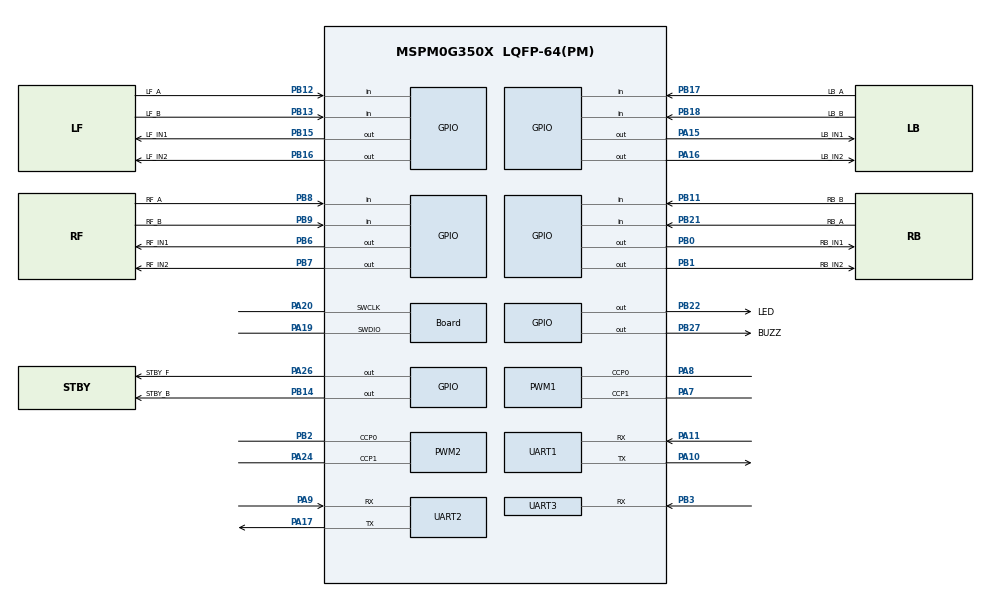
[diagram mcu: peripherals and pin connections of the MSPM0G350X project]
/**
 * These arguments were used when this file was generated. They will be automatically applied on subsequent loads
 * via the GUI or CLI. Run CLI with '--help' for additional information on how to override these arguments.
 * @cliArgs --device "MSPM0G350X" --package "LQFP-64(PM)" --part "Default" --product "mspm0_sdk@1.30.00.03"
 * @versions {"tool":"1.19.0+3426"}
 */

/**
 * Import the modules used in this configuration.
 */
const ADC12         = scripting.addModule("/ti/driverlib/ADC12", {}, false);
const ADC121        = ADC12.addInstance();
const GPIO          = scripting.addModule("/ti/driverlib/GPIO", {}, false);
const GPIO1         = GPIO.addInstance();
const GPIO2         = GPIO.addInstance();
const GPIO3         = GPIO.addInstance();
const GPIO4         = GPIO.addInstance();
const GPIO5         = GPIO.addInstance();
const GPIO6         = GPIO.addInstance();
const PWM           = scripting.addModule("/ti/driverlib/PWM", {}, false);
const PWM1          = PWM.addInstance();
const PWM2          = PWM.addInstance();
const SYSCTL        = scripting.addModule("/ti/driverlib/SYSCTL");
const SYSTICK       = scripting.addModule("/ti/driverlib/SYSTICK");
const TIMER         = scripting.addModule("/ti/driverlib/TIMER", {}, false);
const TIMER1        = TIMER.addInstance();
const TIMER2        = TIMER.addInstance();
const TIMER3        = TIMER.addInstance();
const UART          = scripting.addModule("/ti/driverlib/UART", {}, false);
const UART1         = UART.addInstance();
const UART2         = UART.addInstance();
const UART3         = UART.addInstance();
const ProjectConfig = scripting.addModule("/ti/project_config/ProjectConfig");

/**
 * Write custom configuration values to the imported modules.
 */
const divider6       = system.clockTree["PLL_CLK2X_DIV"];
divider6.divideValue = 4;

const divider7       = system.clockTree["PLL_PDIV"];
divider7.divideValue = 2;

const divider9       = system.clockTree["UDIV"];
divider9.divideValue = 2;

const multiplier2         = system.clockTree["PLL_QDIV"];
multiplier2.multiplyValue = 10;

const mux8       = system.clockTree["HSCLKMUX"];
mux8.inputSelect = "HSCLKMUX_SYSPLL2X";

ADC121.$name                             = "adckey";
ADC121.sampClkDiv                        = "DL_ADC12_CLOCK_DIVIDE_8";
ADC121.enabledInterrupts                 = ["DL_ADC12_INTERRUPT_MEM0_RESULT_LOADED"];
ADC121.adcMem0_name                      = "key";
ADC121.sampleTime0                       = "5 ms";
ADC121.peripheral.$assign                = "ADC0";
ADC121.peripheral.adcPin0.$assign        = "PA27";
ADC121.adcPin0Config.hideOutputInversion = scripting.forceWrite(false);
ADC121.adcPin0Config.$name               = "ti_driverlib_gpio_GPIOPinGeneric8";

const Board                       = scripting.addModule("/ti/driverlib/Board", {}, false);
Board.peripheral.$assign          = "DEBUGSS";
Board.peripheral.swclkPin.$assign = "PA20";
Board.peripheral.swdioPin.$assign = "PA19";

GPIO1.port                               = "PORTB";
GPIO1.$name                              = "REMINDER";
GPIO1.associatedPins.create(2);
GPIO1.associatedPins[0].$name            = "LED";
GPIO1.associatedPins[0].ioStructure      = "SD";
GPIO1.associatedPins[0].assignedPin      = "22";
GPIO1.associatedPins[0].pin.$assign      = "PB22";
GPIO1.associatedPins[1].internalResistor = "PULL_UP";
GPIO1.associatedPins[1].$name            = "BUZZ";
GPIO1.associatedPins[1].pin.$assign      = "PB27";

GPIO2.$name                              = "ENCODER_LF";
GPIO2.port                               = "PORTB";
GPIO2.associatedPins.create(2);
GPIO2.associatedPins[0].direction        = "INPUT";
GPIO2.associatedPins[0].ioStructure      = "SD";
GPIO2.associatedPins[0].interruptEn      = true;
GPIO2.associatedPins[0].internalResistor = "PULL_UP";
GPIO2.associatedPins[0].$name            = "LF_A";
GPIO2.associatedPins[0].assignedPin      = "12";
GPIO2.associatedPins[0].polarity         = "RISE_FALL";
GPIO2.associatedPins[0].pin.$assign      = "PB12";
GPIO2.associatedPins[1].direction        = "INPUT";
GPIO2.associatedPins[1].ioStructure      = "SD";
GPIO2.associatedPins[1].internalResistor = "PULL_UP";
GPIO2.associatedPins[1].$name            = "LF_B";
GPIO2.associatedPins[1].assignedPin      = "13";
GPIO2.associatedPins[1].interruptEn      = true;
GPIO2.associatedPins[1].polarity         = "RISE_FALL";
GPIO2.associatedPins[1].pin.$assign      = "PB13";

GPIO3.$name                              = "ENCODER_LB";
GPIO3.port                               = "PORTB";
GPIO3.associatedPins.create(2);
GPIO3.associatedPins[0].direction        = "INPUT";
GPIO3.associatedPins[0].ioStructure      = "SD";
GPIO3.associatedPins[0].interruptEn      = true;
GPIO3.associatedPins[0].internalResistor = "PULL_UP";
GPIO3.associatedPins[0].$name            = "LB_A";
GPIO3.associatedPins[0].assignedPin      = "17";
GPIO3.associatedPins[0].polarity         = "RISE_FALL";
GPIO3.associatedPins[0].pin.$assign      = "PB17";
GPIO3.associatedPins[1].direction        = "INPUT";
GPIO3.associatedPins[1].ioStructure      = "SD";
GPIO3.associatedPins[1].interruptEn      = true;
GPIO3.associatedPins[1].internalResistor = "PULL_UP";
GPIO3.associatedPins[1].$name            = "LB_B";
GPIO3.associatedPins[1].assignedPin      = "18";
GPIO3.associatedPins[1].polarity         = "RISE_FALL";
GPIO3.associatedPins[1].pin.$assign      = "PB18";

GPIO4.$name                              = "ENCODER_RF";
GPIO4.port                               = "PORTB";
GPIO4.associatedPins.create(2);
GPIO4.associatedPins[0].direction        = "INPUT";
GPIO4.associatedPins[0].ioStructure      = "SD";
GPIO4.associatedPins[0].interruptEn      = true;
GPIO4.associatedPins[0].internalResistor = "PULL_UP";
GPIO4.associatedPins[0].assignedPin      = "8";
GPIO4.associatedPins[0].$name            = "RF_A";
GPIO4.associatedPins[0].polarity         = "RISE_FALL";
GPIO4.associatedPins[0].pin.$assign      = "PB8";
GPIO4.associatedPins[1].direction        = "INPUT";
GPIO4.associatedPins[1].ioStructure      = "SD";
GPIO4.associatedPins[1].interruptEn      = true;
GPIO4.associatedPins[1].internalResistor = "PULL_UP";
GPIO4.associatedPins[1].assignedPin      = "9";
GPIO4.associatedPins[1].$name            = "RF_B";
GPIO4.associatedPins[1].polarity         = "RISE_FALL";
GPIO4.associatedPins[1].pin.$assign      = "PB9";

GPIO5.$name                              = "ENCODER_RB";
GPIO5.port                               = "PORTB";
GPIO5.associatedPins.create(2);
GPIO5.associatedPins[0].direction        = "INPUT";
GPIO5.associatedPins[0].ioStructure      = "SD";
GPIO5.associatedPins[0].interruptEn      = true;
GPIO5.associatedPins[0].internalResistor = "PULL_UP";
GPIO5.associatedPins[0].$name            = "RB_A";
GPIO5.associatedPins[0].assignedPin      = "21";
GPIO5.associatedPins[0].polarity         = "RISE_FALL";
GPIO5.associatedPins[0].pin.$assign      = "PB21";
GPIO5.associatedPins[1].direction        = "INPUT";
GPIO5.associatedPins[1].ioStructure      = "SD";
GPIO5.associatedPins[1].interruptEn      = true;
GPIO5.associatedPins[1].internalResistor = "PULL_UP";
GPIO5.associatedPins[1].assignedPin      = "11";
GPIO5.associatedPins[1].$name            = "RB_B";
GPIO5.associatedPins[1].polarity         = "RISE_FALL";
GPIO5.associatedPins[1].pin.$assign      = "PB11";

GPIO6.$name                              = "MOTOR_DRV";
GPIO6.associatedPins.create(10);
GPIO6.associatedPins[0].$name            = "STBY_F";
GPIO6.associatedPins[0].ioStructure      = "SD";
GPIO6.associatedPins[0].internalResistor = "PULL_UP";
GPIO6.associatedPins[0].pin.$assign      = "PA26";
GPIO6.associatedPins[1].$name            = "STBY_B";
GPIO6.associatedPins[1].ioStructure      = "SD";
GPIO6.associatedPins[1].internalResistor = "PULL_UP";
GPIO6.associatedPins[1].pin.$assign      = "PB14";
GPIO6.associatedPins[2].$name            = "LF_IN1";
GPIO6.associatedPins[2].ioStructure      = "SD";
GPIO6.associatedPins[2].internalResistor = "PULL_UP";
GPIO6.associatedPins[2].pin.$assign      = "PB15";
GPIO6.associatedPins[3].$name            = "LF_IN2";
GPIO6.associatedPins[3].ioStructure      = "SD";
GPIO6.associatedPins[3].internalResistor = "PULL_UP";
GPIO6.associatedPins[3].pin.$assign      = "PB16";
GPIO6.associatedPins[4].$name            = "LB_IN1";
GPIO6.associatedPins[4].ioStructure      = "SD";
GPIO6.associatedPins[4].internalResistor = "PULL_UP";
GPIO6.associatedPins[4].assignedPort     = "PORTA";
GPIO6.associatedPins[4].assignedPin      = "15";
GPIO6.associatedPins[4].pin.$assign      = "PA15";
GPIO6.associatedPins[5].$name            = "LB_IN2";
GPIO6.associatedPins[5].ioStructure      = "SD";
GPIO6.associatedPins[5].internalResistor = "PULL_UP";
GPIO6.associatedPins[5].assignedPort     = "PORTA";
GPIO6.associatedPins[5].assignedPin      = "16";
GPIO6.associatedPins[5].pin.$assign      = "PA16";
GPIO6.associatedPins[6].$name            = "RF_IN1";
GPIO6.associatedPins[6].ioStructure      = "SD";
GPIO6.associatedPins[6].internalResistor = "PULL_UP";
GPIO6.associatedPins[6].pin.$assign      = "PB6";
GPIO6.associatedPins[7].$name            = "RF_IN2";
GPIO6.associatedPins[7].ioStructure      = "SD";
GPIO6.associatedPins[7].internalResistor = "PULL_UP";
GPIO6.associatedPins[7].pin.$assign      = "PB7";
GPIO6.associatedPins[8].$name            = "RB_IN1";
GPIO6.associatedPins[8].ioStructure      = "SD";
GPIO6.associatedPins[8].internalResistor = "PULL_UP";
GPIO6.associatedPins[8].pin.$assign      = "PB0";
GPIO6.associatedPins[9].$name            = "RB_IN2";
GPIO6.associatedPins[9].ioStructure      = "SD";
GPIO6.associatedPins[9].internalResistor = "PULL_UP";
GPIO6.associatedPins[9].pin.$assign      = "PB1";

PWM1.timerStartTimer                    = true;
PWM1.pwmMode                            = "EDGE_ALIGN_UP";
PWM1.clockPrescale                      = 2;
PWM1.timerCount                         = 1600;
PWM1.$name                              = "PWM_MOTOR_L";
PWM1.peripheral.$assign                 = "TIMA0";
PWM1.peripheral.ccp0Pin.$assign         = "PA8";
PWM1.peripheral.ccp1Pin.$assign         = "PA7";
PWM1.PWM_CHANNEL_0.$name                = "ti_driverlib_pwm_PWMTimerCC0";
PWM1.PWM_CHANNEL_1.$name                = "ti_driverlib_pwm_PWMTimerCC1";
PWM1.ccp0PinConfig.direction            = scripting.forceWrite("OUTPUT");
PWM1.ccp0PinConfig.hideOutputInversion  = scripting.forceWrite(false);
PWM1.ccp0PinConfig.onlyInternalResistor = scripting.forceWrite(false);
PWM1.ccp0PinConfig.passedPeripheralType = scripting.forceWrite("Digital");
PWM1.ccp0PinConfig.$name                = "ti_driverlib_gpio_GPIOPinGeneric4";
PWM1.ccp1PinConfig.direction            = scripting.forceWrite("OUTPUT");
PWM1.ccp1PinConfig.hideOutputInversion  = scripting.forceWrite(false);
PWM1.ccp1PinConfig.onlyInternalResistor = scripting.forceWrite(false);
PWM1.ccp1PinConfig.passedPeripheralType = scripting.forceWrite("Digital");
PWM1.ccp1PinConfig.$name                = "ti_driverlib_gpio_GPIOPinGeneric5";

PWM2.$name                              = "PWM_MOTOR_R";
PWM2.clockPrescale                      = 2;
PWM2.timerCount                         = 1600;
PWM2.timerStartTimer                    = true;
PWM2.pwmMode                            = "EDGE_ALIGN_UP";
PWM2.peripheral.$assign                 = "TIMA1";
PWM2.peripheral.ccp0Pin.$assign         = "PB2";
PWM2.peripheral.ccp1Pin.$assign         = "PA24";
PWM2.PWM_CHANNEL_0.$name                = "ti_driverlib_pwm_PWMTimerCC2";
PWM2.PWM_CHANNEL_1.$name                = "ti_driverlib_pwm_PWMTimerCC3";
PWM2.ccp0PinConfig.direction            = scripting.forceWrite("OUTPUT");
PWM2.ccp0PinConfig.hideOutputInversion  = scripting.forceWrite(false);
PWM2.ccp0PinConfig.onlyInternalResistor = scripting.forceWrite(false);
PWM2.ccp0PinConfig.passedPeripheralType = scripting.forceWrite("Digital");
PWM2.ccp0PinConfig.$name                = "ti_driverlib_gpio_GPIOPinGeneric6";
PWM2.ccp1PinConfig.direction            = scripting.forceWrite("OUTPUT");
PWM2.ccp1PinConfig.hideOutputInversion  = scripting.forceWrite(false);
PWM2.ccp1PinConfig.onlyInternalResistor = scripting.forceWrite(false);
PWM2.ccp1PinConfig.passedPeripheralType = scripting.forceWrite("Digital");
PWM2.ccp1PinConfig.$name                = "ti_driverlib_gpio_GPIOPinGeneric7";

SYSCTL.clockTreeEn = true;

SYSTICK.periodEnable      = true;
SYSTICK.period            = 32000;
SYSTICK.interruptEnable   = true;
SYSTICK.interruptPriority = "0";
SYSTICK.systickEnable     = true;

TIMER1.timerStartTimer    = true;
TIMER1.timerMode          = "PERIODIC";
TIMER1.timerClkDiv        = 8;
TIMER1.interrupts         = ["ZERO"];
TIMER1.timerClkPrescale   = 40;
TIMER1.timerPeriod        = "10 ms";
TIMER1.$name              = "ENCODER";
TIMER1.peripheral.$assign = "TIMG7";

TIMER2.timerClkDiv        = 8;
TIMER2.timerClkPrescale   = 40;
TIMER2.timerMode          = "PERIODIC";
TIMER2.timerStartTimer    = true;
TIMER2.interrupts         = ["ZERO"];
TIMER2.$name              = "PID";
TIMER2.timerPeriod        = "10 ms";
TIMER2.peripheral.$assign = "TIMG6";

TIMER3.$name              = "ADC_BUTTON";
TIMER3.timerClkPrescale   = 32;
TIMER3.timerPeriod        = "50 ms";
TIMER3.timerStartTimer    = true;
TIMER3.interrupts         = ["ZERO"];
TIMER3.timerMode          = "PERIODIC";
TIMER3.peripheral.$assign = "TIMG0";

UART1.$name                    = "UART_0";
UART1.enableDMARX              = false;
UART1.enableDMATX              = false;
UART1.enabledInterrupts        = ["RX"];
UART1.rxFifoThreshold          = "DL_UART_RX_FIFO_LEVEL_ONE_ENTRY";
UART1.txFifoThreshold          = "DL_UART_TX_FIFO_LEVEL_3_4_EMPTY";
UART1.peripheral.$assign       = "UART0";
UART1.peripheral.rxPin.$assign = "PA11";
UART1.peripheral.txPin.$assign = "PA10";
UART1.txPinConfig.$name        = "ti_driverlib_gpio_GPIOPinGeneric0";
UART1.rxPinConfig.$name        = "ti_driverlib_gpio_GPIOPinGeneric1";

UART2.$name                    = "UART_1";
UART2.enabledInterrupts        = ["RX"];
UART2.rxFifoThreshold          = "DL_UART_RX_FIFO_LEVEL_ONE_ENTRY";
UART2.txFifoThreshold          = "DL_UART_TX_FIFO_LEVEL_3_4_EMPTY";
UART2.peripheral.$assign       = "UART1";
UART2.peripheral.rxPin.$assign = "PA9";
UART2.peripheral.txPin.$assign = "PA17";
UART2.txPinConfig.$name        = "ti_driverlib_gpio_GPIOPinGeneric2";
UART2.rxPinConfig.$name        = "ti_driverlib_gpio_GPIOPinGeneric3";

UART3.$name                    = "UART_2";
UART3.enableDMARX              = false;
UART3.enableDMATX              = false;
UART3.enabledInterrupts        = ["RX"];
UART3.rxFifoThreshold          = "DL_UART_RX_FIFO_LEVEL_ONE_ENTRY";
UART3.txFifoThreshold          = "DL_UART_TX_FIFO_LEVEL_3_4_EMPTY";
UART3.direction                = "RX";
UART3.peripheral.$assign       = "UART3";
UART3.peripheral.rxPin.$assign = "PB3";
UART3.rxPinConfig.$name        = "ti_driverlib_gpio_GPIOPinGeneric10";

ProjectConfig.deviceSpin = "MSPM0G3507";
scripting.suppress("Migrating requires going through the Switch Board or Device menu in the Device View section\\.", ProjectConfig, "deviceSpin");
